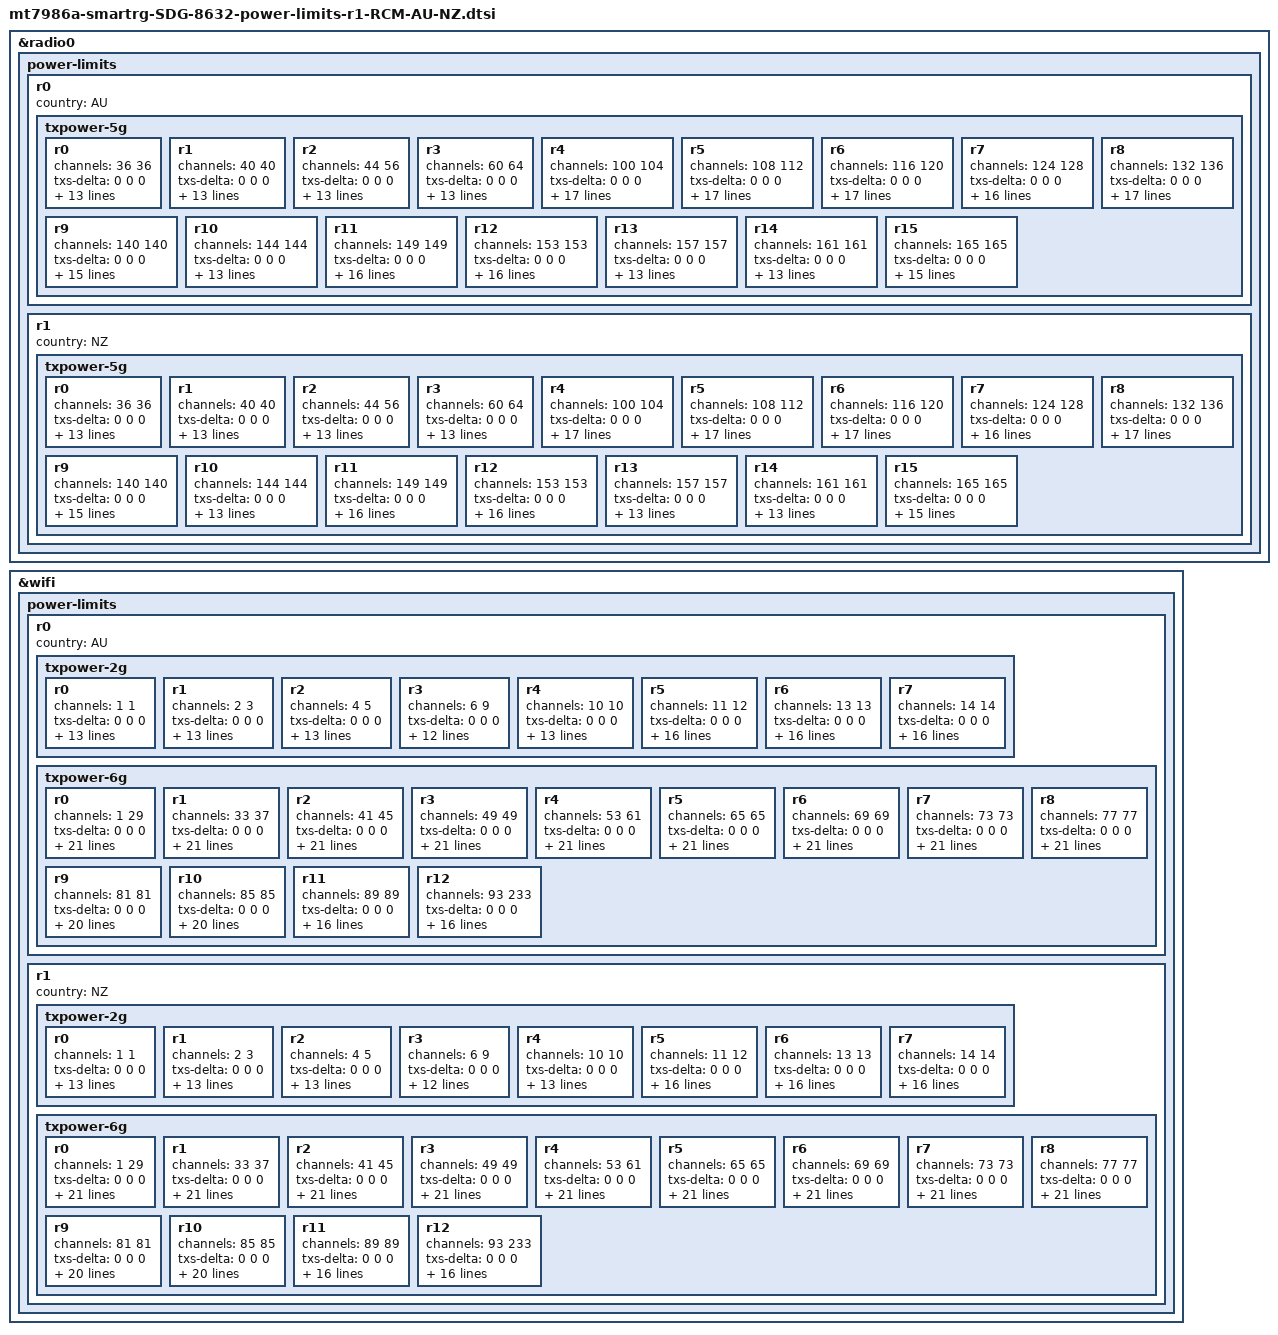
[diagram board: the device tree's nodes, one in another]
// SPDX-License-Identifier: (GPL-2.0 OR MIT)
/*
 * Copyright (C) 2022 SmartRG Inc.
 * Author: Chad Monroe <chad.monroe@smartrg.com>
 */

&radio0 {
	power-limits {
		r0 {
			country = "AU";

			txpower-5g {
				r0 {
					channels = <36 36>;
					txs-delta = <0 0 0>;
					rates-ofdm = <28 28 28 28 28 28 28 28>;
					rates-mcs =
					<2 34 34 34 34 34 34 34 34 34 34>,
					<2 33 33 33 33 33 33 33 33 33 33>;
					rates-ru =
					<5 34 34 34 34 34 34 34 34 34 34 34 34>,
					<2 33 33 33 33 33 33 33 33 33 33 33 33>;
					paths-ofdm = <1 28 28 28 28>;
					paths-ofdm-bf = <1 28 28 28>;
					paths-ru =
					<5 34 34 34 34 34 34 34 34 34 34>,
					<2 33 33 33 33 33 33 33 33 33 33>;
					paths-ru-bf =
					<3 31 31 31 31 31 31 31 31 31 31>,
					<2 0 31 31 31 31 31 31 31 31 31>,
					<2 0 30 30 30 30 30 30 30 30 30>;
				};
				r1 {
					channels = <40 40>;
					txs-delta = <0 0 0>;
					rates-ofdm = <30 30 30 30 30 30 30 30>;
					rates-mcs =
					<2 34 34 34 34 34 34 34 34 34 34>,
					<2 33 33 33 33 33 33 33 33 33 33>;
					rates-ru =
					<5 34 34 34 34 34 34 34 34 34 34 34 34>,
					<2 33 33 33 33 33 33 33 33 33 33 33 33>;
					paths-ofdm = <1 30 30 30 30>;
					paths-ofdm-bf = <1 30 30 30>;
					paths-ru =
					<5 34 34 34 34 34 34 34 34 34 34>,
					<2 33 33 33 33 33 33 33 33 33 33>;
					paths-ru-bf =
					<3 31 31 31 31 31 31 31 31 31 31>,
					<2 0 31 31 31 31 31 31 31 31 31>,
					<2 0 30 30 30 30 30 30 30 30 30>;
				};
				r2 {
					channels = <44 56>;
					txs-delta = <0 0 0>;
					rates-ofdm = <30 30 30 30 30 30 30 30>;
					rates-mcs =
					<2 34 34 34 34 34 34 34 34 34 34>,
					<2 33 33 33 33 33 33 33 33 33 33>;
					rates-ru =
					<5 34 34 34 34 34 34 34 34 34 34 34 34>,
					<2 33 33 33 33 33 33 33 33 33 33 33 33>;
					paths-ofdm = <1 30 30 30 30>;
					paths-ofdm-bf = <1 30 30 30>;
					paths-ru =
					<5 34 34 34 34 34 34 34 34 34 34>,
					<2 33 33 33 33 33 33 33 33 33 33>;
					paths-ru-bf =
					<3 31 31 31 31 31 31 31 31 31 31>,
					<1 0 31 31 31 31 31 31 31 31 31>,
					<3 0 30 30 30 30 30 30 30 30 30>;
				};
				r3 {
					channels = <60 64>;
					txs-delta = <0 0 0>;
					rates-ofdm = <30 30 30 30 30 30 30 30>;
					rates-mcs =
					<1 34 34 34 34 34 34 34 34 34 34>,
					<3 33 33 33 33 33 33 33 33 33 33>;
					rates-ru =
					<4 34 34 34 34 34 34 34 34 34 34 34 34>,
					<3 33 33 33 33 33 33 33 33 33 33 33 33>;
					paths-ofdm = <1 30 30 30 30>;
					paths-ofdm-bf = <1 30 30 30>;
					paths-ru =
					<4 34 34 34 34 34 34 34 34 34 34>,
					<3 33 33 33 33 33 33 33 33 33 33>;
					paths-ru-bf =
					<3 31 31 31 31 31 31 31 31 31 31>,
					<1 0 31 31 31 31 31 31 31 31 31>,
					<3 0 30 30 30 30 30 30 30 30 30>;
				};
				r4 {
					channels = <100 104>;
					txs-delta = <0 0 0>;
					rates-ofdm = <39 39 39 39 39 39 39 39>;
					rates-mcs =
					<1 37 37 37 37 37 37 37 37 37 37>,
					<1 34 34 34 34 34 34 34 34 34 34>,
					<2 32 32 32 32 32 32 32 32 32 32>;
					rates-ru =
					<4 37 37 37 37 37 37 37 37 37 37 37 37>,
					<1 34 34 34 34 34 34 34 34 34 34 34 34>,
					<2 32 32 32 32 32 32 32 32 32 32 32 32>;
					paths-ofdm = <1 39 39 39 39>;
					paths-ofdm-bf = <1 39 39 39>;
					paths-ru =
					<4 37 37 37 37 37 37 37 37 37 37>,
					<1 34 34 34 34 34 34 34 34 34 34>,
					<2 32 32 32 32 32 32 32 32 32 32>;
					paths-ru-bf =
					<3 38 38 38 38 38 38 38 38 38 38>,
					<1 0 38 38 38 38 38 38 38 38 38>,
					<1 0 35 35 35 35 35 35 35 35 35>,
					<2 0 34 34 34 34 34 34 34 34 34>;
				};
				r5 {
					channels = <108 112>;
					txs-delta = <0 0 0>;
					rates-ofdm = <39 39 39 39 39 39 39 39>;
					rates-mcs =
					<1 37 37 37 37 37 37 37 37 37 37>,
					<1 35 35 35 35 35 35 35 35 35 35>,
					<2 32 32 32 32 32 32 32 32 32 32>;
					rates-ru =
					<4 37 37 37 37 37 37 37 37 37 37 37 37>,
					<1 35 35 35 35 35 35 35 35 35 35 35 35>,
					<2 32 32 32 32 32 32 32 32 32 32 32 32>;
					paths-ofdm = <1 39 39 39 39>;
					paths-ofdm-bf = <1 39 39 39>;
					paths-ru =
					<4 37 37 37 37 37 37 37 37 37 37>,
					<1 35 35 35 35 35 35 35 35 35 35>,
					<2 32 32 32 32 32 32 32 32 32 32>;
					paths-ru-bf =
					<3 38 38 38 38 38 38 38 38 38 38>,
					<1 0 38 38 38 38 38 38 38 38 38>,
					<1 0 36 36 36 36 36 36 36 36 36>,
					<2 0 34 34 34 34 34 34 34 34 34>;
				};
				r6 {
					channels = <116 120>;
					txs-delta = <0 0 0>;
					rates-ofdm = <39 39 39 39 39 39 39 39>;
					rates-mcs =
					<1 37 37 37 37 37 37 37 37 37 37>,
					<1 36 36 36 36 36 36 36 36 36 36>,
					<2 39 39 39 39 39 39 39 39 39 39>;
					rates-ru =
					<4 37 37 37 37 37 37 37 37 37 37 37 37>,
					<1 36 36 36 36 36 36 36 36 36 36 36 36>,
					<2 39 39 39 39 39 39 39 39 39 39 39 39>;
					paths-ofdm = <1 39 39 39 39>;
					paths-ofdm-bf = <1 39 39 39>;
					paths-ru =
					<4 37 37 37 37 37 37 37 37 37 37>,
					<1 36 36 36 36 36 36 36 36 36 36>,
					<2 39 39 39 39 39 39 39 39 39 39>;
					paths-ru-bf =
					<3 38 38 38 38 38 38 38 38 38 38>,
					<1 0 38 38 38 38 38 38 38 38 38>,
					<1 0 37 37 37 37 37 37 37 37 37>,
					<2 0 38 38 38 38 38 38 38 38 38>;
				};
				r7 {
					channels = <124 128>;
					txs-delta = <0 0 0>;
					rates-ofdm = <38 38 38 38 38 38 38 38>;
					rates-mcs =
					<1 36 36 36 36 36 36 36 36 36 36>,
					<1 37 37 37 37 37 37 37 37 37 37>,
					<2 39 39 39 39 39 39 39 39 39 39>;
					rates-ru =
					<4 36 36 36 36 36 36 36 36 36 36 36 36>,
					<1 37 37 37 37 37 37 37 37 37 37 37 37>,
					<2 39 39 39 39 39 39 39 39 39 39 39 39>;
					paths-ofdm = <1 38 38 38 38>;
					paths-ofdm-bf = <1 38 38 38>;
					paths-ru =
					<4 36 36 36 36 36 36 36 36 36 36>,
					<1 37 37 37 37 37 37 37 37 37 37>,
					<2 39 39 39 39 39 39 39 39 39 39>;
					paths-ru-bf =
					<3 37 37 37 37 37 37 37 37 37 37>,
					<1 0 37 37 37 37 37 37 37 37 37>,
					<3 0 38 38 38 38 38 38 38 38 38>;
				};
				r8 {
					channels = <132 136>;
					txs-delta = <0 0 0>;
					rates-ofdm = <37 37 37 37 37 37 37 37>;
					rates-mcs =
					<1 35 35 35 35 35 35 35 35 35 35>,
					<1 38 38 38 38 38 38 38 38 38 38>,
					<2 32 32 32 32 32 32 32 32 32 32>;
					rates-ru =
					<4 35 35 35 35 35 35 35 35 35 35 35 35>,
					<1 38 38 38 38 38 38 38 38 38 38 38 38>,
					<2 32 32 32 32 32 32 32 32 32 32 32 32>;
					paths-ofdm = <1 37 37 37 37>;
					paths-ofdm-bf = <1 37 37 37>;
					paths-ru =
					<4 35 35 35 35 35 35 35 35 35 35>,
					<1 38 38 38 38 38 38 38 38 38 38>,
					<2 32 32 32 32 32 32 32 32 32 32>;
					paths-ru-bf =
					<3 36 36 36 36 36 36 36 36 36 36>,
					<1 0 36 36 36 36 36 36 36 36 36>,
					<1 0 39 39 39 39 39 39 39 39 39>,
					<2 0 34 34 34 34 34 34 34 34 34>;
				};
				r9 {
					channels = <140 140>;
					txs-delta = <0 0 0>;
					rates-ofdm = <36 36 36 36 36 36 36 36>;
					rates-mcs =
					<1 34 34 34 34 34 34 34 34 34 34>,
					<1 38 38 38 38 38 38 38 38 38 38>,
					<2 32 32 32 32 32 32 32 32 32 32>;
					rates-ru =
					<4 34 34 34 34 34 34 34 34 34 34 34 34>,
					<1 38 38 38 38 38 38 38 38 38 38 38 38>,
					<2 32 32 32 32 32 32 32 32 32 32 32 32>;
					paths-ofdm = <1 36 36 36 36>;
					paths-ofdm-bf = <1 36 36 36>;
					paths-ru =
					<5 34 34 34 34 34 34 34 34 34 34>,
					<2 32 32 32 32 32 32 32 32 32 32>;
					paths-ru-bf =
					<3 35 35 35 35 35 35 35 35 35 35>,
					<2 0 35 35 35 35 35 35 35 35 35>,
					<2 0 34 34 34 34 34 34 34 34 34>;
				};
				r10 {
					channels = <144 144>;
					txs-delta = <0 0 0>;
					rates-ofdm = <36 36 36 36 36 36 36 36>;
					rates-mcs =
					<2 34 34 34 34 34 34 34 34 34 34>,
					<2 32 32 32 32 32 32 32 32 32 32>;
					rates-ru =
					<5 34 34 34 34 34 34 34 34 34 34 34 34>,
					<2 32 32 32 32 32 32 32 32 32 32 32 32>;
					paths-ofdm = <1 36 36 36 36>;
					paths-ofdm-bf = <1 36 36 36>;
					paths-ru =
					<5 34 34 34 34 34 34 34 34 34 34>,
					<2 32 32 32 32 32 32 32 32 32 32>;
					paths-ru-bf =
					<3 35 35 35 35 35 35 35 35 35 35>,
					<2 0 35 35 35 35 35 35 35 35 35>,
					<2 0 34 34 34 34 34 34 34 34 34>;
				};
				r11 {
					channels = <149 149>;
					txs-delta = <0 0 0>;
					rates-ofdm = <49 49 49 49 49 49 49 49>;
					rates-mcs =
					<1 48 48 48 48 48 48 48 48 48 48>,
					<1 46 46 46 46 46 46 46 46 46 46>,
					<2 45 45 45 45 45 45 45 45 45 45>;
					rates-ru =
					<4 48 48 48 48 48 48 48 48 48 48 48 48>,
					<1 46 46 46 46 46 46 46 46 46 46 46 46>,
					<2 45 45 45 45 45 45 45 45 45 45 45 45>;
					paths-ofdm = <1 49 49 49 49>;
					paths-ofdm-bf = <1 49 49 49>;
					paths-ru =
					<4 48 48 48 48 48 48 48 48 48 48>,
					<1 46 46 46 46 46 46 46 46 46 46>,
					<2 45 45 45 45 45 45 45 45 45 45>;
					paths-ru-bf =
					<3 49 49 49 49 49 49 49 49 49 49>,
					<2 0 49 49 49 49 49 49 49 49 49>,
					<2 0 46 46 46 46 46 46 46 46 46>;
				};
				r12 {
					channels = <153 153>;
					txs-delta = <0 0 0>;
					rates-ofdm = <49 49 49 49 49 49 49 49>;
					rates-mcs =
					<1 48 48 48 48 48 48 48 48 48 48>,
					<1 47 47 47 47 47 47 47 47 47 47>,
					<2 45 45 45 45 45 45 45 45 45 45>;
					rates-ru =
					<4 48 48 48 48 48 48 48 48 48 48 48 48>,
					<1 47 47 47 47 47 47 47 47 47 47 47 47>,
					<2 45 45 45 45 45 45 45 45 45 45 45 45>;
					paths-ofdm = <1 49 49 49 49>;
					paths-ofdm-bf = <1 49 49 49>;
					paths-ru =
					<4 48 48 48 48 48 48 48 48 48 48>,
					<1 46 46 46 46 46 46 46 46 46 46>,
					<2 45 45 45 45 45 45 45 45 45 45>;
					paths-ru-bf =
					<3 49 49 49 49 49 49 49 49 49 49>,
					<2 0 49 49 49 49 49 49 49 49 49>,
					<2 0 46 46 46 46 46 46 46 46 46>;
				};
				r13 {
					channels = <157 157>;
					txs-delta = <0 0 0>;
					rates-ofdm = <48 48 48 48 48 48 48 48>;
					rates-mcs =
					<2 47 47 47 47 47 47 47 47 47 47>,
					<2 45 45 45 45 45 45 45 45 45 45>;
					rates-ru =
					<5 47 47 47 47 47 47 47 47 47 47 47 47>,
					<2 45 45 45 45 45 45 45 45 45 45 45 45>;
					paths-ofdm = <1 48 48 48 48>;
					paths-ofdm-bf = <1 48 48 48>;
					paths-ru =
					<5 47 47 47 47 47 47 47 47 47 47>,
					<2 45 45 45 45 45 45 45 45 45 45>;
					paths-ru-bf =
					<3 48 48 48 48 48 48 48 48 48 48>,
					<2 0 48 48 48 48 48 48 48 48 48>,
					<2 0 46 46 46 46 46 46 46 46 46>;
				};
				r14 {
					channels = <161 161>;
					txs-delta = <0 0 0>;
					rates-ofdm = <47 47 47 47 47 47 47 47>;
					rates-mcs =
					<2 47 47 47 47 47 47 47 47 47 47>,
					<2 45 45 45 45 45 45 45 45 45 45>;
					rates-ru =
					<5 47 47 47 47 47 47 47 47 47 47 47 47>,
					<2 45 45 45 45 45 45 45 45 45 45 45 45>;
					paths-ofdm = <1 47 47 47 47>;
					paths-ofdm-bf = <1 47 47 47>;
					paths-ru =
					<5 47 47 47 47 47 47 47 47 47 47>,
					<2 45 45 45 45 45 45 45 45 45 45>;
					paths-ru-bf =
					<3 48 48 48 48 48 48 48 48 48 48>,
					<2 0 48 48 48 48 48 48 48 48 48>,
					<2 0 46 46 46 46 46 46 46 46 46>;
				};
				r15 {
					channels = <165 165>;
					txs-delta = <0 0 0>;
					rates-ofdm = <46 46 46 46 46 46 46 46>;
					rates-mcs =
					<1 46 46 46 46 46 46 46 46 46 46>,
					<1 47 47 47 47 47 47 47 47 47 47>,
					<2 45 45 45 45 45 45 45 45 45 45>;
					rates-ru =
					<4 46 46 46 46 46 46 46 46 46 46 46 46>,
					<1 47 47 47 47 47 47 47 47 47 47 47 47>,
					<2 45 45 45 45 45 45 45 45 45 45 45 45>;
					paths-ofdm = <1 46 46 46 46>;
					paths-ofdm-bf = <1 46 46 46>;
					paths-ru =
					<4 46 46 46 46 46 46 46 46 46 46>,
					<1 47 47 47 47 47 47 47 47 47 47>,
					<2 45 45 45 45 45 45 45 45 45 45>;
					paths-ru-bf =
					<3 46 46 46 46 46 46 46 46 46 46>,
					<4 0 46 46 46 46 46 46 46 46 46>;
				};
			};
		};

		r1 {
			country = "NZ";

			txpower-5g {
				r0 {
					channels = <36 36>;
					txs-delta = <0 0 0>;
					rates-ofdm = <28 28 28 28 28 28 28 28>;
					rates-mcs =
					<2 34 34 34 34 34 34 34 34 34 34>,
					<2 33 33 33 33 33 33 33 33 33 33>;
					rates-ru =
					<5 34 34 34 34 34 34 34 34 34 34 34 34>,
					<2 33 33 33 33 33 33 33 33 33 33 33 33>;
					paths-ofdm = <1 28 28 28 28>;
					paths-ofdm-bf = <1 28 28 28>;
					paths-ru =
					<5 34 34 34 34 34 34 34 34 34 34>,
					<2 33 33 33 33 33 33 33 33 33 33>;
					paths-ru-bf =
					<3 31 31 31 31 31 31 31 31 31 31>,
					<2 0 31 31 31 31 31 31 31 31 31>,
					<2 0 30 30 30 30 30 30 30 30 30>;
				};
				r1 {
					channels = <40 40>;
					txs-delta = <0 0 0>;
					rates-ofdm = <30 30 30 30 30 30 30 30>;
					rates-mcs =
					<2 34 34 34 34 34 34 34 34 34 34>,
					<2 33 33 33 33 33 33 33 33 33 33>;
					rates-ru =
					<5 34 34 34 34 34 34 34 34 34 34 34 34>,
					<2 33 33 33 33 33 33 33 33 33 33 33 33>;
					paths-ofdm = <1 30 30 30 30>;
					paths-ofdm-bf = <1 30 30 30>;
					paths-ru =
					<5 34 34 34 34 34 34 34 34 34 34>,
					<2 33 33 33 33 33 33 33 33 33 33>;
					paths-ru-bf =
					<3 31 31 31 31 31 31 31 31 31 31>,
					<2 0 31 31 31 31 31 31 31 31 31>,
					<2 0 30 30 30 30 30 30 30 30 30>;
				};
				r2 {
					channels = <44 56>;
					txs-delta = <0 0 0>;
					rates-ofdm = <30 30 30 30 30 30 30 30>;
					rates-mcs =
					<2 34 34 34 34 34 34 34 34 34 34>,
					<2 33 33 33 33 33 33 33 33 33 33>;
					rates-ru =
					<5 34 34 34 34 34 34 34 34 34 34 34 34>,
					<2 33 33 33 33 33 33 33 33 33 33 33 33>;
					paths-ofdm = <1 30 30 30 30>;
					paths-ofdm-bf = <1 30 30 30>;
					paths-ru =
					<5 34 34 34 34 34 34 34 34 34 34>,
					<2 33 33 33 33 33 33 33 33 33 33>;
					paths-ru-bf =
					<3 31 31 31 31 31 31 31 31 31 31>,
					<1 0 31 31 31 31 31 31 31 31 31>,
					<3 0 30 30 30 30 30 30 30 30 30>;
				};
				r3 {
					channels = <60 64>;
					txs-delta = <0 0 0>;
					rates-ofdm = <30 30 30 30 30 30 30 30>;
					rates-mcs =
					<1 34 34 34 34 34 34 34 34 34 34>,
					<3 33 33 33 33 33 33 33 33 33 33>;
					rates-ru =
					<4 34 34 34 34 34 34 34 34 34 34 34 34>,
					<3 33 33 33 33 33 33 33 33 33 33 33 33>;
					paths-ofdm = <1 30 30 30 30>;
					paths-ofdm-bf = <1 30 30 30>;
					paths-ru =
					<4 34 34 34 34 34 34 34 34 34 34>,
					<3 33 33 33 33 33 33 33 33 33 33>;
					paths-ru-bf =
					<3 31 31 31 31 31 31 31 31 31 31>,
					<1 0 31 31 31 31 31 31 31 31 31>,
					<3 0 30 30 30 30 30 30 30 30 30>;
				};
				r4 {
					channels = <100 104>;
					txs-delta = <0 0 0>;
					rates-ofdm = <39 39 39 39 39 39 39 39>;
					rates-mcs =
					<1 37 37 37 37 37 37 37 37 37 37>,
					<1 34 34 34 34 34 34 34 34 34 34>,
					<2 32 32 32 32 32 32 32 32 32 32>;
					rates-ru =
					<4 37 37 37 37 37 37 37 37 37 37 37 37>,
					<1 34 34 34 34 34 34 34 34 34 34 34 34>,
					<2 32 32 32 32 32 32 32 32 32 32 32 32>;
					paths-ofdm = <1 39 39 39 39>;
					paths-ofdm-bf = <1 39 39 39>;
					paths-ru =
					<4 37 37 37 37 37 37 37 37 37 37>,
					<1 34 34 34 34 34 34 34 34 34 34>,
					<2 32 32 32 32 32 32 32 32 32 32>;
					paths-ru-bf =
					<3 38 38 38 38 38 38 38 38 38 38>,
					<1 0 38 38 38 38 38 38 38 38 38>,
					<1 0 35 35 35 35 35 35 35 35 35>,
					<2 0 34 34 34 34 34 34 34 34 34>;
				};
				r5 {
					channels = <108 112>;
					txs-delta = <0 0 0>;
					rates-ofdm = <39 39 39 39 39 39 39 39>;
					rates-mcs =
					<1 37 37 37 37 37 37 37 37 37 37>,
					<1 35 35 35 35 35 35 35 35 35 35>,
					<2 32 32 32 32 32 32 32 32 32 32>;
					rates-ru =
					<4 37 37 37 37 37 37 37 37 37 37 37 37>,
					<1 35 35 35 35 35 35 35 35 35 35 35 35>,
					<2 32 32 32 32 32 32 32 32 32 32 32 32>;
					paths-ofdm = <1 39 39 39 39>;
					paths-ofdm-bf = <1 39 39 39>;
					paths-ru =
					<4 37 37 37 37 37 37 37 37 37 37>,
					<1 35 35 35 35 35 35 35 35 35 35>,
					<2 32 32 32 32 32 32 32 32 32 32>;
					paths-ru-bf =
					<3 38 38 38 38 38 38 38 38 38 38>,
					<1 0 38 38 38 38 38 38 38 38 38>,
					<1 0 36 36 36 36 36 36 36 36 36>,
					<2 0 34 34 34 34 34 34 34 34 34>;
				};
				r6 {
					channels = <116 120>;
					txs-delta = <0 0 0>;
					rates-ofdm = <39 39 39 39 39 39 39 39>;
					rates-mcs =
					<1 37 37 37 37 37 37 37 37 37 37>,
					<1 36 36 36 36 36 36 36 36 36 36>,
					<2 39 39 39 39 39 39 39 39 39 39>;
					rates-ru =
					<4 37 37 37 37 37 37 37 37 37 37 37 37>,
					<1 36 36 36 36 36 36 36 36 36 36 36 36>,
					<2 39 39 39 39 39 39 39 39 39 39 39 39>;
					paths-ofdm = <1 39 39 39 39>;
					paths-ofdm-bf = <1 39 39 39>;
					paths-ru =
					<4 37 37 37 37 37 37 37 37 37 37>,
					<1 36 36 36 36 36 36 36 36 36 36>,
					<2 39 39 39 39 39 39 39 39 39 39>;
					paths-ru-bf =
					<3 38 38 38 38 38 38 38 38 38 38>,
					<1 0 38 38 38 38 38 38 38 38 38>,
					<1 0 37 37 37 37 37 37 37 37 37>,
					<2 0 38 38 38 38 38 38 38 38 38>;
				};
				r7 {
					channels = <124 128>;
					txs-delta = <0 0 0>;
					rates-ofdm = <38 38 38 38 38 38 38 38>;
					rates-mcs =
					<1 36 36 36 36 36 36 36 36 36 36>,
					<1 37 37 37 37 37 37 37 37 37 37>,
					<2 39 39 39 39 39 39 39 39 39 39>;
					rates-ru =
					<4 36 36 36 36 36 36 36 36 36 36 36 36>,
					<1 37 37 37 37 37 37 37 37 37 37 37 37>,
					<2 39 39 39 39 39 39 39 39 39 39 39 39>;
					paths-ofdm = <1 38 38 38 38>;
					paths-ofdm-bf = <1 38 38 38>;
					paths-ru =
					<4 36 36 36 36 36 36 36 36 36 36>,
					<1 37 37 37 37 37 37 37 37 37 37>,
					<2 39 39 39 39 39 39 39 39 39 39>;
					paths-ru-bf =
					<3 37 37 37 37 37 37 37 37 37 37>,
					<1 0 37 37 37 37 37 37 37 37 37>,
					<3 0 38 38 38 38 38 38 38 38 38>;
				};
				r8 {
					channels = <132 136>;
					txs-delta = <0 0 0>;
					rates-ofdm = <37 37 37 37 37 37 37 37>;
					rates-mcs =
					<1 35 35 35 35 35 35 35 35 35 35>,
					<1 38 38 38 38 38 38 38 38 38 38>,
					<2 32 32 32 32 32 32 32 32 32 32>;
					rates-ru =
					<4 35 35 35 35 35 35 35 35 35 35 35 35>,
					<1 38 38 38 38 38 38 38 38 38 38 38 38>,
					<2 32 32 32 32 32 32 32 32 32 32 32 32>;
					paths-ofdm = <1 37 37 37 37>;
					paths-ofdm-bf = <1 37 37 37>;
					paths-ru =
					<4 35 35 35 35 35 35 35 35 35 35>,
					<1 38 38 38 38 38 38 38 38 38 38>,
					<2 32 32 32 32 32 32 32 32 32 32>;
					paths-ru-bf =
					<3 36 36 36 36 36 36 36 36 36 36>,
					<1 0 36 36 36 36 36 36 36 36 36>,
					<1 0 39 39 39 39 39 39 39 39 39>,
					<2 0 34 34 34 34 34 34 34 34 34>;
				};
				r9 {
					channels = <140 140>;
					txs-delta = <0 0 0>;
					rates-ofdm = <36 36 36 36 36 36 36 36>;
					rates-mcs =
					<1 34 34 34 34 34 34 34 34 34 34>,
					<1 38 38 38 38 38 38 38 38 38 38>,
					<2 32 32 32 32 32 32 32 32 32 32>;
					rates-ru =
					<4 34 34 34 34 34 34 34 34 34 34 34 34>,
					<1 38 38 38 38 38 38 38 38 38 38 38 38>,
					<2 32 32 32 32 32 32 32 32 32 32 32 32>;
					paths-ofdm = <1 36 36 36 36>;
					paths-ofdm-bf = <1 36 36 36>;
					paths-ru =
					<5 34 34 34 34 34 34 34 34 34 34>,
					<2 32 32 32 32 32 32 32 32 32 32>;
					paths-ru-bf =
					<3 35 35 35 35 35 35 35 35 35 35>,
					<2 0 35 35 35 35 35 35 35 35 35>,
					<2 0 34 34 34 34 34 34 34 34 34>;
				};
				r10 {
					channels = <144 144>;
					txs-delta = <0 0 0>;
					rates-ofdm = <36 36 36 36 36 36 36 36>;
					rates-mcs =
					<2 34 34 34 34 34 34 34 34 34 34>,
					<2 32 32 32 32 32 32 32 32 32 32>;
					rates-ru =
					<5 34 34 34 34 34 34 34 34 34 34 34 34>,
					<2 32 32 32 32 32 32 32 32 32 32 32 32>;
					paths-ofdm = <1 36 36 36 36>;
					paths-ofdm-bf = <1 36 36 36>;
					paths-ru =
					<5 34 34 34 34 34 34 34 34 34 34>,
					<2 32 32 32 32 32 32 32 32 32 32>;
					paths-ru-bf =
					<3 35 35 35 35 35 35 35 35 35 35>,
					<2 0 35 35 35 35 35 35 35 35 35>,
					<2 0 34 34 34 34 34 34 34 34 34>;
				};
				r11 {
					channels = <149 149>;
					txs-delta = <0 0 0>;
					rates-ofdm = <49 49 49 49 49 49 49 49>;
					rates-mcs =
					<1 48 48 48 48 48 48 48 48 48 48>,
					<1 46 46 46 46 46 46 46 46 46 46>,
					<2 45 45 45 45 45 45 45 45 45 45>;
					rates-ru =
					<4 48 48 48 48 48 48 48 48 48 48 48 48>,
					<1 46 46 46 46 46 46 46 46 46 46 46 46>,
					<2 45 45 45 45 45 45 45 45 45 45 45 45>;
					paths-ofdm = <1 49 49 49 49>;
					paths-ofdm-bf = <1 49 49 49>;
					paths-ru =
					<4 48 48 48 48 48 48 48 48 48 48>,
					<1 46 46 46 46 46 46 46 46 46 46>,
					<2 45 45 45 45 45 45 45 45 45 45>;
					paths-ru-bf =
					<3 49 49 49 49 49 49 49 49 49 49>,
					<2 0 49 49 49 49 49 49 49 49 49>,
					<2 0 46 46 46 46 46 46 46 46 46>;
				};
				r12 {
					channels = <153 153>;
					txs-delta = <0 0 0>;
					rates-ofdm = <49 49 49 49 49 49 49 49>;
					rates-mcs =
					<1 48 48 48 48 48 48 48 48 48 48>,
					<1 47 47 47 47 47 47 47 47 47 47>,
					<2 45 45 45 45 45 45 45 45 45 45>;
					rates-ru =
					<4 48 48 48 48 48 48 48 48 48 48 48 48>,
					<1 47 47 47 47 47 47 47 47 47 47 47 47>,
					<2 45 45 45 45 45 45 45 45 45 45 45 45>;
					paths-ofdm = <1 49 49 49 49>;
					paths-ofdm-bf = <1 49 49 49>;
					paths-ru =
					<4 48 48 48 48 48 48 48 48 48 48>,
					<1 46 46 46 46 46 46 46 46 46 46>,
					<2 45 45 45 45 45 45 45 45 45 45>;
					paths-ru-bf =
					<3 49 49 49 49 49 49 49 49 49 49>,
					<2 0 49 49 49 49 49 49 49 49 49>,
					<2 0 46 46 46 46 46 46 46 46 46>;
				};
				r13 {
					channels = <157 157>;
					txs-delta = <0 0 0>;
					rates-ofdm = <48 48 48 48 48 48 48 48>;
					rates-mcs =
					<2 47 47 47 47 47 47 47 47 47 47>,
					<2 45 45 45 45 45 45 45 45 45 45>;
					rates-ru =
					<5 47 47 47 47 47 47 47 47 47 47 47 47>,
					<2 45 45 45 45 45 45 45 45 45 45 45 45>;
					paths-ofdm = <1 48 48 48 48>;
					paths-ofdm-bf = <1 48 48 48>;
					paths-ru =
					<5 47 47 47 47 47 47 47 47 47 47>,
					<2 45 45 45 45 45 45 45 45 45 45>;
					paths-ru-bf =
					<3 48 48 48 48 48 48 48 48 48 48>,
					<2 0 48 48 48 48 48 48 48 48 48>,
					<2 0 46 46 46 46 46 46 46 46 46>;
				};
				r14 {
					channels = <161 161>;
					txs-delta = <0 0 0>;
					rates-ofdm = <47 47 47 47 47 47 47 47>;
					rates-mcs =
					<2 47 47 47 47 47 47 47 47 47 47>,
					<2 45 45 45 45 45 45 45 45 45 45>;
					rates-ru =
					<5 47 47 47 47 47 47 47 47 47 47 47 47>,
					<2 45 45 45 45 45 45 45 45 45 45 45 45>;
					paths-ofdm = <1 47 47 47 47>;
					paths-ofdm-bf = <1 47 47 47>;
					paths-ru =
					<5 47 47 47 47 47 47 47 47 47 47>,
					<2 45 45 45 45 45 45 45 45 45 45>;
					paths-ru-bf =
					<3 48 48 48 48 48 48 48 48 48 48>,
					<2 0 48 48 48 48 48 48 48 48 48>,
					<2 0 46 46 46 46 46 46 46 46 46>;
				};
				r15 {
					channels = <165 165>;
					txs-delta = <0 0 0>;
					rates-ofdm = <46 46 46 46 46 46 46 46>;
					rates-mcs =
					<1 46 46 46 46 46 46 46 46 46 46>,
					<1 47 47 47 47 47 47 47 47 47 47>,
					<2 45 45 45 45 45 45 45 45 45 45>;
					rates-ru =
					<4 46 46 46 46 46 46 46 46 46 46 46 46>,
					<1 47 47 47 47 47 47 47 47 47 47 47 47>,
					<2 45 45 45 45 45 45 45 45 45 45 45 45>;
					paths-ofdm = <1 46 46 46 46>;
					paths-ofdm-bf = <1 46 46 46>;
					paths-ru =
					<4 46 46 46 46 46 46 46 46 46 46>,
					<1 47 47 47 47 47 47 47 47 47 47>,
					<2 45 45 45 45 45 45 45 45 45 45>;
					paths-ru-bf =
					<3 46 46 46 46 46 46 46 46 46 46>,
					<4 0 46 46 46 46 46 46 46 46 46>;
				};
			};
		};
	};
};

&wifi {
	power-limits {
		r0 {
			country = "AU";

			txpower-2g {
				r0 {
					channels = <1 1>;
					txs-delta = <0 0 0>;
					rates-cck = <50 50 50 50>;
					rates-ofdm = <56 56 56 56 56 56 56 56>;
					rates-mcs =
					<4 56 56 56 56 56 56 56 56 56 56>;
					rates-ru =
					<7 56 56 56 56 56 56 56 56 56 56 56 56>;
					paths-cck = <50 50 50 50>;
					paths-ofdm = <1 56 56 56 56>;
					paths-ofdm-bf = <1 50 50 50>;
					paths-ru =
					<5 56 56 56 56 56 56 56 56 56 56>,
					<2 27 27 27 27 27 27 27 27 27 27>;
					paths-ru-bf =
					<3 26 26 26 26 26 26 26 26 26 26>,
					<1 0 26 26 26 26 26 26 26 26 26>,
					<3 0 27 27 27 27 27 27 27 27 27>;
				};
				r1 {
					channels = <2 3>;
					txs-delta = <0 0 0>;
					rates-cck = <51 51 51 51>;
					rates-ofdm = <57 57 57 57 57 57 57 57>;
					rates-mcs =
					<4 56 56 56 56 56 56 56 56 56 56>;
					rates-ru =
					<7 56 56 56 56 56 56 56 56 56 56 56 56>;
					paths-cck = <51 51 51 51>;
					paths-ofdm = <1 57 57 57 57>;
					paths-ofdm-bf = <1 51 51 51>;
					paths-ru =
					<5 56 56 56 56 56 56 56 56 56 56>,
					<2 27 27 27 27 27 27 27 27 27 27>;
					paths-ru-bf =
					<3 26 26 26 26 26 26 26 26 26 26>,
					<1 0 26 26 26 26 26 26 26 26 26>,
					<3 0 27 27 27 27 27 27 27 27 27>;
				};
				r2 {
					channels = <4 5>;
					txs-delta = <0 0 0>;
					rates-cck = <51 51 51 51>;
					rates-ofdm = <57 57 57 57 57 57 57 57>;
					rates-mcs =
					<4 56 56 56 56 56 56 56 56 56 56>;
					rates-ru =
					<7 56 56 56 56 56 56 56 56 56 56 56 56>;
					paths-cck = <51 51 51 51>;
					paths-ofdm = <1 57 57 57 57>;
					paths-ofdm-bf = <1 51 51 51>;
					paths-ru =
					<5 56 56 56 56 56 56 56 56 56 56>,
					<2 26 26 26 26 26 26 26 26 26 26>;
					paths-ru-bf =
					<3 25 25 25 25 25 25 25 25 25 25>,
					<1 0 25 25 25 25 25 25 25 25 25>,
					<3 0 26 26 26 26 26 26 26 26 26>;
				};
				r3 {
					channels = <6 9>;
					txs-delta = <0 0 0>;
					rates-cck = <51 51 51 51>;
					rates-ofdm = <57 57 57 57 57 57 57 57>;
					rates-mcs =
					<4 56 56 56 56 56 56 56 56 56 56>;
					rates-ru =
					<7 56 56 56 56 56 56 56 56 56 56 56 56>;
					paths-cck = <51 51 51 51>;
					paths-ofdm = <1 57 57 57 57>;
					paths-ofdm-bf = <1 51 51 51>;
					paths-ru =
					<5 56 56 56 56 56 56 56 56 56 56>,
					<2 25 25 25 25 25 25 25 25 25 25>;
					paths-ru-bf =
					<3 25 25 25 25 25 25 25 25 25 25>,
					<4 0 25 25 25 25 25 25 25 25 25>;
				};
				r4 {
					channels = <10 10>;
					txs-delta = <0 0 0>;
					rates-cck = <51 51 51 51>;
					rates-ofdm = <57 57 57 57 57 57 57 57>;
					rates-mcs =
					<4 56 56 56 56 56 56 56 56 56 56>;
					rates-ru =
					<7 56 56 56 56 56 56 56 56 56 56 56 56>;
					paths-cck = <51 51 51 51>;
					paths-ofdm = <1 57 57 57 57>;
					paths-ofdm-bf = <1 51 51 51>;
					paths-ru =
					<5 56 56 56 56 56 56 56 56 56 56>,
					<2 26 26 26 26 26 26 26 26 26 26>;
					paths-ru-bf =
					<3 25 25 25 25 25 25 25 25 25 25>,
					<1 0 25 25 25 25 25 25 25 25 25>,
					<3 0 26 26 26 26 26 26 26 26 26>;
				};
				r5 {
					channels = <11 12>;
					txs-delta = <0 0 0>;
					rates-cck = <51 51 51 51>;
					rates-ofdm = <57 57 57 57 57 57 57 57>;
					rates-mcs =
					<1 56 56 56 56 56 56 56 56 56 56>,
					<3 55 55 55 55 55 55 55 55 55 55>;
					rates-ru =
					<4 56 56 56 56 56 56 56 56 56 56 56 56>,
					<3 55 55 55 55 55 55 55 55 55 55 55 55>;
					paths-cck = <51 51 51 51>;
					paths-ofdm = <1 57 57 57 57>;
					paths-ofdm-bf = <1 51 51 51>;
					paths-ru =
					<4 56 56 56 56 56 56 56 56 56 56>,
					<1 55 55 55 55 55 55 55 55 55 55>,
					<2 26 26 26 26 26 26 26 26 26 26>;
					paths-ru-bf =
					<3 25 25 25 25 25 25 25 25 25 25>,
					<1 0 25 25 25 25 25 25 25 25 25>,
					<3 0 26 26 26 26 26 26 26 26 26>;
				};
				r6 {
					channels = <13 13>;
					txs-delta = <0 0 0>;
					rates-cck = <51 51 51 51>;
					rates-ofdm = <56 56 56 56 56 56 56 56>;
					rates-mcs =
					<1 56 56 56 56 56 56 56 56 56 56>,
					<3 55 55 55 55 55 55 55 55 55 55>;
					rates-ru =
					<4 56 56 56 56 56 56 56 56 56 56 56 56>,
					<3 55 55 55 55 55 55 55 55 55 55 55 55>;
					paths-cck = <51 51 51 51>;
					paths-ofdm = <1 56 56 56 56>;
					paths-ofdm-bf = <1 51 51 51>;
					paths-ru =
					<4 56 56 56 56 56 56 56 56 56 56>,
					<1 55 55 55 55 55 55 55 55 55 55>,
					<2 26 26 26 26 26 26 26 26 26 26>;
					paths-ru-bf =
					<3 25 25 25 25 25 25 25 25 25 25>,
					<1 0 25 25 25 25 25 25 25 25 25>,
					<3 0 26 26 26 26 26 26 26 26 26>;
				};
				r7 {
					channels = <14 14>;
					txs-delta = <0 0 0>;
					rates-cck = <50 50 50 50>;
					rates-ofdm = <56 56 56 56 56 56 56 56>;
					rates-mcs =
					<1 56 56 56 56 56 56 56 56 56 56>,
					<1 55 55 55 55 55 55 55 55 55 55>,
					<2 37 37 37 37 37 37 37 37 37 37>;
					rates-ru =
					<4 56 56 56 56 56 56 56 56 56 56 56 56>,
					<3 55 55 55 55 55 55 55 55 55 55 55 55>;
					paths-cck = <50 50 50 50>;
					paths-ofdm = <1 56 56 56 56>;
					paths-ofdm-bf = <1 50 50 50>;
					paths-ru =
					<4 56 56 56 56 56 56 56 56 56 56>,
					<1 55 55 55 55 55 55 55 55 55 55>,
					<2 25 25 25 25 25 25 25 25 25 25>;
					paths-ru-bf =
					<3 25 25 25 25 25 25 25 25 25 25>,
					<4 0 25 25 25 25 25 25 25 25 25>;
				};
			};

			txpower-6g {
				r0 {
					channels = <1 29>;
					txs-delta = <0 0 0>;
					rates-ofdm = <26 26 26 26 26 26 26 26>;
					rates-mcs =
					<1 29 29 29 29 29 29 29 29 29 29>,
					<1 31 31 31 31 31 31 31 31 31 31>,
					<1 29 29 29 29 29 29 29 29 29 29>,
					<1 31 31 31 31 31 31 31 31 31 31>;
					rates-ru =
					<4 29 29 29 29 29 29 29 29 29 29 29 29>,
					<1 31 31 31 31 31 31 31 31 31 31 31 31>,
					<1 29 29 29 29 29 29 29 29 29 29 29 29>,
					<1 31 31 31 31 31 31 31 31 31 31 31 31>;
					paths-ofdm = <1 26 26 26 26>;
					paths-ofdm-bf = <1 26 26 26>;
					paths-ru =
					<4 29 29 29 29 29 29 29 29 29 29>,
					<1 31 31 31 31 31 31 31 31 31 31>,
					<1 29 29 29 29 29 29 29 29 29 29>,
					<1 31 31 31 31 31 31 31 31 31 31>;
					paths-ru-bf =
					<3 20 20 20 20 20 20 20 20 20 20>,
					<1 0 20 20 20 20 20 20 20 20 20>,
					<1 0 21 21 21 21 21 21 21 21 21>,
					<1 0 20 20 20 20 20 20 20 20 20>,
					<1 0 22 22 22 22 22 22 22 22 22>;
				};
				r1 {
					channels = <33 37>;
					txs-delta = <0 0 0>;
					rates-ofdm = <26 26 26 26 26 26 26 26>;
					rates-mcs =
					<1 29 29 29 29 29 29 29 29 29 29>,
					<1 31 31 31 31 31 31 31 31 31 31>,
					<1 29 29 29 29 29 29 29 29 29 29>,
					<1 31 31 31 31 31 31 31 31 31 31>;
					rates-ru =
					<4 29 29 29 29 29 29 29 29 29 29 29 29>,
					<1 31 31 31 31 31 31 31 31 31 31 31 31>,
					<1 29 29 29 29 29 29 29 29 29 29 29 29>,
					<1 31 31 31 31 31 31 31 31 31 31 31 31>;
					paths-ofdm = <1 26 26 26 26>;
					paths-ofdm-bf = <1 26 26 26>;
					paths-ru =
					<4 29 29 29 29 29 29 29 29 29 29>,
					<1 31 31 31 31 31 31 31 31 31 31>,
					<1 29 29 29 29 29 29 29 29 29 29>,
					<1 31 31 31 31 31 31 31 31 31 31>;
					paths-ru-bf =
					<3 20 20 20 20 20 20 20 20 20 20>,
					<1 0 20 20 20 20 20 20 20 20 20>,
					<1 0 21 21 21 21 21 21 21 21 21>,
					<1 0 20 20 20 20 20 20 20 20 20>,
					<1 0 21 21 21 21 21 21 21 21 21>;
				};
				r2 {
					channels = <41 45>;
					txs-delta = <0 0 0>;
					rates-ofdm = <26 26 26 26 26 26 26 26>;
					rates-mcs =
					<1 29 29 29 29 29 29 29 29 29 29>,
					<1 30 30 30 30 30 30 30 30 30 30>,
					<1 29 29 29 29 29 29 29 29 29 29>,
					<1 31 31 31 31 31 31 31 31 31 31>;
					rates-ru =
					<4 29 29 29 29 29 29 29 29 29 29 29 29>,
					<1 30 30 30 30 30 30 30 30 30 30 30 30>,
					<1 29 29 29 29 29 29 29 29 29 29 29 29>,
					<1 31 31 31 31 31 31 31 31 31 31 31 31>;
					paths-ofdm = <1 26 26 26 26>;
					paths-ofdm-bf = <1 26 26 26>;
					paths-ru =
					<4 29 29 29 29 29 29 29 29 29 29>,
					<1 30 30 30 30 30 30 30 30 30 30>,
					<1 29 29 29 29 29 29 29 29 29 29>,
					<1 31 31 31 31 31 31 31 31 31 31>;
					paths-ru-bf =
					<3 20 20 20 20 20 20 20 20 20 20>,
					<1 0 20 20 20 20 20 20 20 20 20>,
					<1 0 21 21 21 21 21 21 21 21 21>,
					<1 0 20 20 20 20 20 20 20 20 20>,
					<1 0 21 21 21 21 21 21 21 21 21>;
				};
				r3 {
					channels = <49 49>;
					txs-delta = <0 0 0>;
					rates-ofdm = <26 26 26 26 26 26 26 26>;
					rates-mcs =
					<1 29 29 29 29 29 29 29 29 29 29>,
					<1 30 30 30 30 30 30 30 30 30 30>,
					<1 29 29 29 29 29 29 29 29 29 29>,
					<1 31 31 31 31 31 31 31 31 31 31>;
					rates-ru =
					<4 29 29 29 29 29 29 29 29 29 29 29 29>,
					<1 30 30 30 30 30 30 30 30 30 30 30 30>,
					<1 29 29 29 29 29 29 29 29 29 29 29 29>,
					<1 31 31 31 31 31 31 31 31 31 31 31 31>;
					paths-ofdm = <1 26 26 26 26>;
					paths-ofdm-bf = <1 26 26 26>;
					paths-ru =
					<4 29 29 29 29 29 29 29 29 29 29>,
					<1 30 30 30 30 30 30 30 30 30 30>,
					<1 29 29 29 29 29 29 29 29 29 29>,
					<1 31 31 31 31 31 31 31 31 31 31>;
					paths-ru-bf =
					<3 20 20 20 20 20 20 20 20 20 20>,
					<1 0 20 20 20 20 20 20 20 20 20>,
					<1 0 21 21 21 21 21 21 21 21 21>,
					<1 0 19 19 19 19 19 19 19 19 19>,
					<1 0 21 21 21 21 21 21 21 21 21>;
				};
				r4 {
					channels = <53 61>;
					txs-delta = <0 0 0>;
					rates-ofdm = <26 26 26 26 26 26 26 26>;
					rates-mcs =
					<1 29 29 29 29 29 29 29 29 29 29>,
					<1 30 30 30 30 30 30 30 30 30 30>,
					<1 28 28 28 28 28 28 28 28 28 28>,
					<1 31 31 31 31 31 31 31 31 31 31>;
					rates-ru =
					<4 29 29 29 29 29 29 29 29 29 29 29 29>,
					<1 30 30 30 30 30 30 30 30 30 30 30 30>,
					<1 28 28 28 28 28 28 28 28 28 28 28 28>,
					<1 31 31 31 31 31 31 31 31 31 31 31 31>;
					paths-ofdm = <1 26 26 26 26>;
					paths-ofdm-bf = <1 26 26 26>;
					paths-ru =
					<4 29 29 29 29 29 29 29 29 29 29>,
					<1 30 30 30 30 30 30 30 30 30 30>,
					<1 28 28 28 28 28 28 28 28 28 28>,
					<1 31 31 31 31 31 31 31 31 31 31>;
					paths-ru-bf =
					<3 20 20 20 20 20 20 20 20 20 20>,
					<1 0 20 20 20 20 20 20 20 20 20>,
					<1 0 21 21 21 21 21 21 21 21 21>,
					<1 0 19 19 19 19 19 19 19 19 19>,
					<1 0 21 21 21 21 21 21 21 21 21>;
				};
				r5 {
					channels = <65 65>;
					txs-delta = <0 0 0>;
					rates-ofdm = <26 26 26 26 26 26 26 26>;
					rates-mcs =
					<1 28 28 28 28 28 28 28 28 28 28>,
					<1 30 30 30 30 30 30 30 30 30 30>,
					<1 28 28 28 28 28 28 28 28 28 28>,
					<1 31 31 31 31 31 31 31 31 31 31>;
					rates-ru =
					<4 28 28 28 28 28 28 28 28 28 28 28 28>,
					<1 30 30 30 30 30 30 30 30 30 30 30 30>,
					<1 28 28 28 28 28 28 28 28 28 28 28 28>,
					<1 31 31 31 31 31 31 31 31 31 31 31 31>;
					paths-ofdm = <1 26 26 26 26>;
					paths-ofdm-bf = <1 26 26 26>;
					paths-ru =
					<4 28 28 28 28 28 28 28 28 28 28>,
					<1 30 30 30 30 30 30 30 30 30 30>,
					<1 28 28 28 28 28 28 28 28 28 28>,
					<1 31 31 31 31 31 31 31 31 31 31>;
					paths-ru-bf =
					<3 20 20 20 20 20 20 20 20 20 20>,
					<1 0 20 20 20 20 20 20 20 20 20>,
					<1 0 21 21 21 21 21 21 21 21 21>,
					<1 0 18 18 18 18 18 18 18 18 18>,
					<1 0 20 20 20 20 20 20 20 20 20>;
				};
				r6 {
					channels = <69 69>;
					txs-delta = <0 0 0>;
					rates-ofdm = <26 26 26 26 26 26 26 26>;
					rates-mcs =
					<1 28 28 28 28 28 28 28 28 28 28>,
					<1 29 29 29 29 29 29 29 29 29 29>,
					<1 28 28 28 28 28 28 28 28 28 28>,
					<1 31 31 31 31 31 31 31 31 31 31>;
					rates-ru =
					<4 28 28 28 28 28 28 28 28 28 28 28 28>,
					<1 29 29 29 29 29 29 29 29 29 29 29 29>,
					<1 28 28 28 28 28 28 28 28 28 28 28 28>,
					<1 31 31 31 31 31 31 31 31 31 31 31 31>;
					paths-ofdm = <1 26 26 26 26>;
					paths-ofdm-bf = <1 26 26 26>;
					paths-ru =
					<4 28 28 28 28 28 28 28 28 28 28>,
					<1 29 29 29 29 29 29 29 29 29 29>,
					<1 28 28 28 28 28 28 28 28 28 28>,
					<1 31 31 31 31 31 31 31 31 31 31>;
					paths-ru-bf =
					<3 20 20 20 20 20 20 20 20 20 20>,
					<1 0 20 20 20 20 20 20 20 20 20>,
					<1 0 21 21 21 21 21 21 21 21 21>,
					<1 0 18 18 18 18 18 18 18 18 18>,
					<1 0 20 20 20 20 20 20 20 20 20>;
				};
				r7 {
					channels = <73 73>;
					txs-delta = <0 0 0>;
					rates-ofdm = <26 26 26 26 26 26 26 26>;
					rates-mcs =
					<1 28 28 28 28 28 28 28 28 28 28>,
					<1 29 29 29 29 29 29 29 29 29 29>,
					<1 28 28 28 28 28 28 28 28 28 28>,
					<1 31 31 31 31 31 31 31 31 31 31>;
					rates-ru =
					<4 28 28 28 28 28 28 28 28 28 28 28 28>,
					<1 29 29 29 29 29 29 29 29 29 29 29 29>,
					<1 28 28 28 28 28 28 28 28 28 28 28 28>,
					<1 31 31 31 31 31 31 31 31 31 31 31 31>;
					paths-ofdm = <1 26 26 26 26>;
					paths-ofdm-bf = <1 26 26 26>;
					paths-ru =
					<4 28 28 28 28 28 28 28 28 28 28>,
					<1 29 29 29 29 29 29 29 29 29 29>,
					<1 28 28 28 28 28 28 28 28 28 28>,
					<1 31 31 31 31 31 31 31 31 31 31>;
					paths-ru-bf =
					<3 19 19 19 19 19 19 19 19 19 19>,
					<1 0 19 19 19 19 19 19 19 19 19>,
					<1 0 20 20 20 20 20 20 20 20 20>,
					<1 0 18 18 18 18 18 18 18 18 18>,
					<1 0 20 20 20 20 20 20 20 20 20>;
				};
				r8 {
					channels = <77 77>;
					txs-delta = <0 0 0>;
					rates-ofdm = <26 26 26 26 26 26 26 26>;
					rates-mcs =
					<1 27 27 27 27 27 27 27 27 27 27>,
					<1 29 29 29 29 29 29 29 29 29 29>,
					<1 28 28 28 28 28 28 28 28 28 28>,
					<1 31 31 31 31 31 31 31 31 31 31>;
					rates-ru =
					<4 27 27 27 27 27 27 27 27 27 27 27 27>,
					<1 29 29 29 29 29 29 29 29 29 29 29 29>,
					<1 28 28 28 28 28 28 28 28 28 28 28 28>,
					<1 31 31 31 31 31 31 31 31 31 31 31 31>;
					paths-ofdm = <1 26 26 26 26>;
					paths-ofdm-bf = <1 26 26 26>;
					paths-ru =
					<4 27 27 27 27 27 27 27 27 27 27>,
					<1 29 29 29 29 29 29 29 29 29 29>,
					<1 28 28 28 28 28 28 28 28 28 28>,
					<1 31 31 31 31 31 31 31 31 31 31>;
					paths-ru-bf =
					<3 19 19 19 19 19 19 19 19 19 19>,
					<1 0 19 19 19 19 19 19 19 19 19>,
					<1 0 20 20 20 20 20 20 20 20 20>,
					<1 0 18 18 18 18 18 18 18 18 18>,
					<1 0 20 20 20 20 20 20 20 20 20>;
				};
				r9 {
					channels = <81 81>;
					txs-delta = <0 0 0>;
					rates-ofdm = <25 25 25 25 25 25 25 25>;
					rates-mcs =
					<1 27 27 27 27 27 27 27 27 27 27>,
					<1 29 29 29 29 29 29 29 29 29 29>,
					<1 28 28 28 28 28 28 28 28 28 28>,
					<1 31 31 31 31 31 31 31 31 31 31>;
					rates-ru =
					<4 27 27 27 27 27 27 27 27 27 27 27 27>,
					<1 29 29 29 29 29 29 29 29 29 29 29 29>,
					<1 28 28 28 28 28 28 28 28 28 28 28 28>,
					<1 31 31 31 31 31 31 31 31 31 31 31 31>;
					paths-ofdm = <1 25 25 25 25>;
					paths-ofdm-bf = <1 25 25 25>;
					paths-ru =
					<4 27 27 27 27 27 27 27 27 27 27>,
					<1 29 29 29 29 29 29 29 29 29 29>,
					<1 28 28 28 28 28 28 28 28 28 28>,
					<1 31 31 31 31 31 31 31 31 31 31>;
					paths-ru-bf =
					<3 18 18 18 18 18 18 18 18 18 18>,
					<2 0 18 18 18 18 18 18 18 18 18>,
					<1 0 17 17 17 17 17 17 17 17 17>,
					<1 0 20 20 20 20 20 20 20 20 20>;
				};
				r10 {
					channels = <85 85>;
					txs-delta = <0 0 0>;
					rates-ofdm = <25 25 25 25 25 25 25 25>;
					rates-mcs =
					<1 26 26 26 26 26 26 26 26 26 26>,
					<1 29 29 29 29 29 29 29 29 29 29>,
					<1 28 28 28 28 28 28 28 28 28 28>,
					<1 31 31 31 31 31 31 31 31 31 31>;
					rates-ru =
					<4 26 26 26 26 26 26 26 26 26 26 26 26>,
					<1 29 29 29 29 29 29 29 29 29 29 29 29>,
					<1 28 28 28 28 28 28 28 28 28 28 28 28>,
					<1 31 31 31 31 31 31 31 31 31 31 31 31>;
					paths-ofdm = <1 25 25 25 25>;
					paths-ofdm-bf = <1 25 25 25>;
					paths-ru =
					<4 26 26 26 26 26 26 26 26 26 26>,
					<1 29 29 29 29 29 29 29 29 29 29>,
					<1 28 28 28 28 28 28 28 28 28 28>,
					<1 31 31 31 31 31 31 31 31 31 31>;
					paths-ru-bf =
					<3 18 18 18 18 18 18 18 18 18 18>,
					<2 0 18 18 18 18 18 18 18 18 18>,
					<1 0 17 17 17 17 17 17 17 17 17>,
					<1 0 20 20 20 20 20 20 20 20 20>;
				};
				r11 {
					channels = <89 89>;
					txs-delta = <0 0 0>;
					rates-ofdm = <25 25 25 25 25 25 25 25>;
					rates-mcs =
					<1 26 26 26 26 26 26 26 26 26 26>,
					<2 28 28 28 28 28 28 28 28 28 28>,
					<1 31 31 31 31 31 31 31 31 31 31>;
					rates-ru =
					<4 26 26 26 26 26 26 26 26 26 26 26 26>,
					<2 28 28 28 28 28 28 28 28 28 28 28 28>,
					<1 31 31 31 31 31 31 31 31 31 31 31 31>;
					paths-ofdm = <1 25 25 25 25>;
					paths-ofdm-bf = <1 25 25 25>;
					paths-ru =
					<4 26 26 26 26 26 26 26 26 26 26>,
					<2 28 28 28 28 28 28 28 28 28 28>,
					<1 31 31 31 31 31 31 31 31 31 31>;
					paths-ru-bf =
					<3 17 17 17 17 17 17 17 17 17 17>,
					<3 0 17 17 17 17 17 17 17 17 17>,
					<1 0 20 20 20 20 20 20 20 20 20>;
				};
				r12 {
					channels = <93 233>;
					txs-delta = <0 0 0>;
					rates-ofdm = <24 24 24 24 24 24 24 24>;
					rates-mcs =
					<1 26 26 26 26 26 26 26 26 26 26>,
					<2 28 28 28 28 28 28 28 28 28 28>,
					<1 31 31 31 31 31 31 31 31 31 31>;
					rates-ru =
					<4 26 26 26 26 26 26 26 26 26 26 26 26>,
					<2 28 28 28 28 28 28 28 28 28 28 28 28>,
					<1 31 31 31 31 31 31 31 31 31 31 31 31>;
					paths-ofdm = <1 24 24 24 24>;
					paths-ofdm-bf = <1 24 24 24>;
					paths-ru =
					<4 26 26 26 26 26 26 26 26 26 26>,
					<2 28 28 28 28 28 28 28 28 28 28>,
					<1 31 31 31 31 31 31 31 31 31 31>;
					paths-ru-bf =
					<3 17 17 17 17 17 17 17 17 17 17>,
					<3 0 17 17 17 17 17 17 17 17 17>,
					<1 0 20 20 20 20 20 20 20 20 20>;
				};
			};
		};

		r1 {
			country = "NZ";

			txpower-2g {
				r0 {
					channels = <1 1>;
					txs-delta = <0 0 0>;
					rates-cck = <50 50 50 50>;
					rates-ofdm = <56 56 56 56 56 56 56 56>;
					rates-mcs =
					<4 56 56 56 56 56 56 56 56 56 56>;
					rates-ru =
					<7 56 56 56 56 56 56 56 56 56 56 56 56>;
					paths-cck = <50 50 50 50>;
					paths-ofdm = <1 56 56 56 56>;
					paths-ofdm-bf = <1 50 50 50>;
					paths-ru =
					<5 56 56 56 56 56 56 56 56 56 56>,
					<2 27 27 27 27 27 27 27 27 27 27>;
					paths-ru-bf =
					<3 26 26 26 26 26 26 26 26 26 26>,
					<1 0 26 26 26 26 26 26 26 26 26>,
					<3 0 27 27 27 27 27 27 27 27 27>;
				};
				r1 {
					channels = <2 3>;
					txs-delta = <0 0 0>;
					rates-cck = <51 51 51 51>;
					rates-ofdm = <57 57 57 57 57 57 57 57>;
					rates-mcs =
					<4 56 56 56 56 56 56 56 56 56 56>;
					rates-ru =
					<7 56 56 56 56 56 56 56 56 56 56 56 56>;
					paths-cck = <51 51 51 51>;
					paths-ofdm = <1 57 57 57 57>;
					paths-ofdm-bf = <1 51 51 51>;
					paths-ru =
					<5 56 56 56 56 56 56 56 56 56 56>,
					<2 27 27 27 27 27 27 27 27 27 27>;
					paths-ru-bf =
					<3 26 26 26 26 26 26 26 26 26 26>,
					<1 0 26 26 26 26 26 26 26 26 26>,
					<3 0 27 27 27 27 27 27 27 27 27>;
				};
				r2 {
					channels = <4 5>;
					txs-delta = <0 0 0>;
					rates-cck = <51 51 51 51>;
					rates-ofdm = <57 57 57 57 57 57 57 57>;
					rates-mcs =
					<4 56 56 56 56 56 56 56 56 56 56>;
					rates-ru =
					<7 56 56 56 56 56 56 56 56 56 56 56 56>;
					paths-cck = <51 51 51 51>;
					paths-ofdm = <1 57 57 57 57>;
					paths-ofdm-bf = <1 51 51 51>;
					paths-ru =
					<5 56 56 56 56 56 56 56 56 56 56>,
					<2 26 26 26 26 26 26 26 26 26 26>;
					paths-ru-bf =
					<3 25 25 25 25 25 25 25 25 25 25>,
					<1 0 25 25 25 25 25 25 25 25 25>,
					<3 0 26 26 26 26 26 26 26 26 26>;
				};
				r3 {
					channels = <6 9>;
					txs-delta = <0 0 0>;
					rates-cck = <51 51 51 51>;
					rates-ofdm = <57 57 57 57 57 57 57 57>;
					rates-mcs =
					<4 56 56 56 56 56 56 56 56 56 56>;
					rates-ru =
					<7 56 56 56 56 56 56 56 56 56 56 56 56>;
					paths-cck = <51 51 51 51>;
					paths-ofdm = <1 57 57 57 57>;
					paths-ofdm-bf = <1 51 51 51>;
					paths-ru =
					<5 56 56 56 56 56 56 56 56 56 56>,
					<2 25 25 25 25 25 25 25 25 25 25>;
					paths-ru-bf =
					<3 25 25 25 25 25 25 25 25 25 25>,
					<4 0 25 25 25 25 25 25 25 25 25>;
				};
				r4 {
					channels = <10 10>;
					txs-delta = <0 0 0>;
					rates-cck = <51 51 51 51>;
					rates-ofdm = <57 57 57 57 57 57 57 57>;
					rates-mcs =
					<4 56 56 56 56 56 56 56 56 56 56>;
					rates-ru =
					<7 56 56 56 56 56 56 56 56 56 56 56 56>;
					paths-cck = <51 51 51 51>;
					paths-ofdm = <1 57 57 57 57>;
					paths-ofdm-bf = <1 51 51 51>;
					paths-ru =
					<5 56 56 56 56 56 56 56 56 56 56>,
					<2 26 26 26 26 26 26 26 26 26 26>;
					paths-ru-bf =
					<3 25 25 25 25 25 25 25 25 25 25>,
					<1 0 25 25 25 25 25 25 25 25 25>,
					<3 0 26 26 26 26 26 26 26 26 26>;
				};
				r5 {
					channels = <11 12>;
					txs-delta = <0 0 0>;
					rates-cck = <51 51 51 51>;
					rates-ofdm = <57 57 57 57 57 57 57 57>;
					rates-mcs =
					<1 56 56 56 56 56 56 56 56 56 56>,
					<3 55 55 55 55 55 55 55 55 55 55>;
					rates-ru =
					<4 56 56 56 56 56 56 56 56 56 56 56 56>,
					<3 55 55 55 55 55 55 55 55 55 55 55 55>;
					paths-cck = <51 51 51 51>;
					paths-ofdm = <1 57 57 57 57>;
					paths-ofdm-bf = <1 51 51 51>;
					paths-ru =
					<4 56 56 56 56 56 56 56 56 56 56>,
					<1 55 55 55 55 55 55 55 55 55 55>,
					<2 26 26 26 26 26 26 26 26 26 26>;
					paths-ru-bf =
					<3 25 25 25 25 25 25 25 25 25 25>,
					<1 0 25 25 25 25 25 25 25 25 25>,
					<3 0 26 26 26 26 26 26 26 26 26>;
				};
				r6 {
					channels = <13 13>;
					txs-delta = <0 0 0>;
					rates-cck = <51 51 51 51>;
					rates-ofdm = <56 56 56 56 56 56 56 56>;
					rates-mcs =
					<1 56 56 56 56 56 56 56 56 56 56>,
					<3 55 55 55 55 55 55 55 55 55 55>;
					rates-ru =
					<4 56 56 56 56 56 56 56 56 56 56 56 56>,
					<3 55 55 55 55 55 55 55 55 55 55 55 55>;
					paths-cck = <51 51 51 51>;
					paths-ofdm = <1 56 56 56 56>;
					paths-ofdm-bf = <1 51 51 51>;
					paths-ru =
					<4 56 56 56 56 56 56 56 56 56 56>,
					<1 55 55 55 55 55 55 55 55 55 55>,
					<2 26 26 26 26 26 26 26 26 26 26>;
					paths-ru-bf =
					<3 25 25 25 25 25 25 25 25 25 25>,
					<1 0 25 25 25 25 25 25 25 25 25>,
					<3 0 26 26 26 26 26 26 26 26 26>;
				};
				r7 {
					channels = <14 14>;
					txs-delta = <0 0 0>;
					rates-cck = <50 50 50 50>;
					rates-ofdm = <56 56 56 56 56 56 56 56>;
					rates-mcs =
					<1 56 56 56 56 56 56 56 56 56 56>,
					<1 55 55 55 55 55 55 55 55 55 55>,
					<2 37 37 37 37 37 37 37 37 37 37>;
					rates-ru =
					<4 56 56 56 56 56 56 56 56 56 56 56 56>,
					<3 55 55 55 55 55 55 55 55 55 55 55 55>;
					paths-cck = <50 50 50 50>;
					paths-ofdm = <1 56 56 56 56>;
					paths-ofdm-bf = <1 50 50 50>;
					paths-ru =
					<4 56 56 56 56 56 56 56 56 56 56>,
					<1 55 55 55 55 55 55 55 55 55 55>,
					<2 25 25 25 25 25 25 25 25 25 25>;
					paths-ru-bf =
					<3 25 25 25 25 25 25 25 25 25 25>,
					<4 0 25 25 25 25 25 25 25 25 25>;
				};
			};

			txpower-6g {
				r0 {
					channels = <1 29>;
					txs-delta = <0 0 0>;
					rates-ofdm = <26 26 26 26 26 26 26 26>;
					rates-mcs =
					<1 29 29 29 29 29 29 29 29 29 29>,
					<1 31 31 31 31 31 31 31 31 31 31>,
					<1 29 29 29 29 29 29 29 29 29 29>,
					<1 31 31 31 31 31 31 31 31 31 31>;
					rates-ru =
					<4 29 29 29 29 29 29 29 29 29 29 29 29>,
					<1 31 31 31 31 31 31 31 31 31 31 31 31>,
					<1 29 29 29 29 29 29 29 29 29 29 29 29>,
					<1 31 31 31 31 31 31 31 31 31 31 31 31>;
					paths-ofdm = <1 26 26 26 26>;
					paths-ofdm-bf = <1 26 26 26>;
					paths-ru =
					<4 29 29 29 29 29 29 29 29 29 29>,
					<1 31 31 31 31 31 31 31 31 31 31>,
					<1 29 29 29 29 29 29 29 29 29 29>,
					<1 31 31 31 31 31 31 31 31 31 31>;
					paths-ru-bf =
					<3 20 20 20 20 20 20 20 20 20 20>,
					<1 0 20 20 20 20 20 20 20 20 20>,
					<1 0 21 21 21 21 21 21 21 21 21>,
					<1 0 20 20 20 20 20 20 20 20 20>,
					<1 0 22 22 22 22 22 22 22 22 22>;
				};
				r1 {
					channels = <33 37>;
					txs-delta = <0 0 0>;
					rates-ofdm = <26 26 26 26 26 26 26 26>;
					rates-mcs =
					<1 29 29 29 29 29 29 29 29 29 29>,
					<1 31 31 31 31 31 31 31 31 31 31>,
					<1 29 29 29 29 29 29 29 29 29 29>,
					<1 31 31 31 31 31 31 31 31 31 31>;
					rates-ru =
					<4 29 29 29 29 29 29 29 29 29 29 29 29>,
					<1 31 31 31 31 31 31 31 31 31 31 31 31>,
					<1 29 29 29 29 29 29 29 29 29 29 29 29>,
					<1 31 31 31 31 31 31 31 31 31 31 31 31>;
					paths-ofdm = <1 26 26 26 26>;
					paths-ofdm-bf = <1 26 26 26>;
					paths-ru =
					<4 29 29 29 29 29 29 29 29 29 29>,
					<1 31 31 31 31 31 31 31 31 31 31>,
					<1 29 29 29 29 29 29 29 29 29 29>,
					<1 31 31 31 31 31 31 31 31 31 31>;
					paths-ru-bf =
					<3 20 20 20 20 20 20 20 20 20 20>,
					<1 0 20 20 20 20 20 20 20 20 20>,
					<1 0 21 21 21 21 21 21 21 21 21>,
					<1 0 20 20 20 20 20 20 20 20 20>,
					<1 0 21 21 21 21 21 21 21 21 21>;
				};
				r2 {
					channels = <41 45>;
					txs-delta = <0 0 0>;
					rates-ofdm = <26 26 26 26 26 26 26 26>;
					rates-mcs =
					<1 29 29 29 29 29 29 29 29 29 29>,
					<1 30 30 30 30 30 30 30 30 30 30>,
					<1 29 29 29 29 29 29 29 29 29 29>,
					<1 31 31 31 31 31 31 31 31 31 31>;
					rates-ru =
					<4 29 29 29 29 29 29 29 29 29 29 29 29>,
					<1 30 30 30 30 30 30 30 30 30 30 30 30>,
					<1 29 29 29 29 29 29 29 29 29 29 29 29>,
					<1 31 31 31 31 31 31 31 31 31 31 31 31>;
					paths-ofdm = <1 26 26 26 26>;
					paths-ofdm-bf = <1 26 26 26>;
					paths-ru =
					<4 29 29 29 29 29 29 29 29 29 29>,
					<1 30 30 30 30 30 30 30 30 30 30>,
					<1 29 29 29 29 29 29 29 29 29 29>,
					<1 31 31 31 31 31 31 31 31 31 31>;
					paths-ru-bf =
					<3 20 20 20 20 20 20 20 20 20 20>,
					<1 0 20 20 20 20 20 20 20 20 20>,
					<1 0 21 21 21 21 21 21 21 21 21>,
					<1 0 20 20 20 20 20 20 20 20 20>,
					<1 0 21 21 21 21 21 21 21 21 21>;
				};
				r3 {
					channels = <49 49>;
					txs-delta = <0 0 0>;
					rates-ofdm = <26 26 26 26 26 26 26 26>;
					rates-mcs =
					<1 29 29 29 29 29 29 29 29 29 29>,
					<1 30 30 30 30 30 30 30 30 30 30>,
					<1 29 29 29 29 29 29 29 29 29 29>,
					<1 31 31 31 31 31 31 31 31 31 31>;
					rates-ru =
					<4 29 29 29 29 29 29 29 29 29 29 29 29>,
					<1 30 30 30 30 30 30 30 30 30 30 30 30>,
					<1 29 29 29 29 29 29 29 29 29 29 29 29>,
					<1 31 31 31 31 31 31 31 31 31 31 31 31>;
					paths-ofdm = <1 26 26 26 26>;
					paths-ofdm-bf = <1 26 26 26>;
					paths-ru =
					<4 29 29 29 29 29 29 29 29 29 29>,
					<1 30 30 30 30 30 30 30 30 30 30>,
					<1 29 29 29 29 29 29 29 29 29 29>,
					<1 31 31 31 31 31 31 31 31 31 31>;
					paths-ru-bf =
					<3 20 20 20 20 20 20 20 20 20 20>,
					<1 0 20 20 20 20 20 20 20 20 20>,
					<1 0 21 21 21 21 21 21 21 21 21>,
					<1 0 19 19 19 19 19 19 19 19 19>,
					<1 0 21 21 21 21 21 21 21 21 21>;
				};
				r4 {
					channels = <53 61>;
					txs-delta = <0 0 0>;
					rates-ofdm = <26 26 26 26 26 26 26 26>;
					rates-mcs =
					<1 29 29 29 29 29 29 29 29 29 29>,
					<1 30 30 30 30 30 30 30 30 30 30>,
					<1 28 28 28 28 28 28 28 28 28 28>,
					<1 31 31 31 31 31 31 31 31 31 31>;
					rates-ru =
					<4 29 29 29 29 29 29 29 29 29 29 29 29>,
					<1 30 30 30 30 30 30 30 30 30 30 30 30>,
					<1 28 28 28 28 28 28 28 28 28 28 28 28>,
					<1 31 31 31 31 31 31 31 31 31 31 31 31>;
					paths-ofdm = <1 26 26 26 26>;
					paths-ofdm-bf = <1 26 26 26>;
					paths-ru =
					<4 29 29 29 29 29 29 29 29 29 29>,
					<1 30 30 30 30 30 30 30 30 30 30>,
					<1 28 28 28 28 28 28 28 28 28 28>,
					<1 31 31 31 31 31 31 31 31 31 31>;
					paths-ru-bf =
					<3 20 20 20 20 20 20 20 20 20 20>,
					<1 0 20 20 20 20 20 20 20 20 20>,
					<1 0 21 21 21 21 21 21 21 21 21>,
					<1 0 19 19 19 19 19 19 19 19 19>,
					<1 0 21 21 21 21 21 21 21 21 21>;
				};
				r5 {
					channels = <65 65>;
					txs-delta = <0 0 0>;
					rates-ofdm = <26 26 26 26 26 26 26 26>;
					rates-mcs =
					<1 28 28 28 28 28 28 28 28 28 28>,
					<1 30 30 30 30 30 30 30 30 30 30>,
					<1 28 28 28 28 28 28 28 28 28 28>,
					<1 31 31 31 31 31 31 31 31 31 31>;
					rates-ru =
					<4 28 28 28 28 28 28 28 28 28 28 28 28>,
					<1 30 30 30 30 30 30 30 30 30 30 30 30>,
					<1 28 28 28 28 28 28 28 28 28 28 28 28>,
					<1 31 31 31 31 31 31 31 31 31 31 31 31>;
					paths-ofdm = <1 26 26 26 26>;
					paths-ofdm-bf = <1 26 26 26>;
					paths-ru =
					<4 28 28 28 28 28 28 28 28 28 28>,
					<1 30 30 30 30 30 30 30 30 30 30>,
					<1 28 28 28 28 28 28 28 28 28 28>,
					<1 31 31 31 31 31 31 31 31 31 31>;
					paths-ru-bf =
					<3 20 20 20 20 20 20 20 20 20 20>,
					<1 0 20 20 20 20 20 20 20 20 20>,
					<1 0 21 21 21 21 21 21 21 21 21>,
					<1 0 18 18 18 18 18 18 18 18 18>,
					<1 0 20 20 20 20 20 20 20 20 20>;
				};
				r6 {
					channels = <69 69>;
					txs-delta = <0 0 0>;
					rates-ofdm = <26 26 26 26 26 26 26 26>;
					rates-mcs =
					<1 28 28 28 28 28 28 28 28 28 28>,
					<1 29 29 29 29 29 29 29 29 29 29>,
					<1 28 28 28 28 28 28 28 28 28 28>,
					<1 31 31 31 31 31 31 31 31 31 31>;
					rates-ru =
					<4 28 28 28 28 28 28 28 28 28 28 28 28>,
					<1 29 29 29 29 29 29 29 29 29 29 29 29>,
					<1 28 28 28 28 28 28 28 28 28 28 28 28>,
					<1 31 31 31 31 31 31 31 31 31 31 31 31>;
					paths-ofdm = <1 26 26 26 26>;
					paths-ofdm-bf = <1 26 26 26>;
					paths-ru =
					<4 28 28 28 28 28 28 28 28 28 28>,
					<1 29 29 29 29 29 29 29 29 29 29>,
					<1 28 28 28 28 28 28 28 28 28 28>,
					<1 31 31 31 31 31 31 31 31 31 31>;
					paths-ru-bf =
					<3 20 20 20 20 20 20 20 20 20 20>,
					<1 0 20 20 20 20 20 20 20 20 20>,
					<1 0 21 21 21 21 21 21 21 21 21>,
					<1 0 18 18 18 18 18 18 18 18 18>,
					<1 0 20 20 20 20 20 20 20 20 20>;
				};
				r7 {
					channels = <73 73>;
					txs-delta = <0 0 0>;
					rates-ofdm = <26 26 26 26 26 26 26 26>;
					rates-mcs =
					<1 28 28 28 28 28 28 28 28 28 28>,
					<1 29 29 29 29 29 29 29 29 29 29>,
					<1 28 28 28 28 28 28 28 28 28 28>,
					<1 31 31 31 31 31 31 31 31 31 31>;
					rates-ru =
					<4 28 28 28 28 28 28 28 28 28 28 28 28>,
					<1 29 29 29 29 29 29 29 29 29 29 29 29>,
					<1 28 28 28 28 28 28 28 28 28 28 28 28>,
					<1 31 31 31 31 31 31 31 31 31 31 31 31>;
					paths-ofdm = <1 26 26 26 26>;
					paths-ofdm-bf = <1 26 26 26>;
					paths-ru =
					<4 28 28 28 28 28 28 28 28 28 28>,
					<1 29 29 29 29 29 29 29 29 29 29>,
					<1 28 28 28 28 28 28 28 28 28 28>,
					<1 31 31 31 31 31 31 31 31 31 31>;
					paths-ru-bf =
					<3 19 19 19 19 19 19 19 19 19 19>,
					<1 0 19 19 19 19 19 19 19 19 19>,
					<1 0 20 20 20 20 20 20 20 20 20>,
					<1 0 18 18 18 18 18 18 18 18 18>,
					<1 0 20 20 20 20 20 20 20 20 20>;
				};
				r8 {
					channels = <77 77>;
					txs-delta = <0 0 0>;
					rates-ofdm = <26 26 26 26 26 26 26 26>;
					rates-mcs =
					<1 27 27 27 27 27 27 27 27 27 27>,
					<1 29 29 29 29 29 29 29 29 29 29>,
					<1 28 28 28 28 28 28 28 28 28 28>,
					<1 31 31 31 31 31 31 31 31 31 31>;
					rates-ru =
					<4 27 27 27 27 27 27 27 27 27 27 27 27>,
					<1 29 29 29 29 29 29 29 29 29 29 29 29>,
					<1 28 28 28 28 28 28 28 28 28 28 28 28>,
					<1 31 31 31 31 31 31 31 31 31 31 31 31>;
					paths-ofdm = <1 26 26 26 26>;
					paths-ofdm-bf = <1 26 26 26>;
					paths-ru =
					<4 27 27 27 27 27 27 27 27 27 27>,
					<1 29 29 29 29 29 29 29 29 29 29>,
					<1 28 28 28 28 28 28 28 28 28 28>,
					<1 31 31 31 31 31 31 31 31 31 31>;
					paths-ru-bf =
					<3 19 19 19 19 19 19 19 19 19 19>,
					<1 0 19 19 19 19 19 19 19 19 19>,
					<1 0 20 20 20 20 20 20 20 20 20>,
					<1 0 18 18 18 18 18 18 18 18 18>,
					<1 0 20 20 20 20 20 20 20 20 20>;
				};
				r9 {
					channels = <81 81>;
					txs-delta = <0 0 0>;
					rates-ofdm = <25 25 25 25 25 25 25 25>;
					rates-mcs =
					<1 27 27 27 27 27 27 27 27 27 27>,
					<1 29 29 29 29 29 29 29 29 29 29>,
					<1 28 28 28 28 28 28 28 28 28 28>,
					<1 31 31 31 31 31 31 31 31 31 31>;
					rates-ru =
					<4 27 27 27 27 27 27 27 27 27 27 27 27>,
					<1 29 29 29 29 29 29 29 29 29 29 29 29>,
					<1 28 28 28 28 28 28 28 28 28 28 28 28>,
					<1 31 31 31 31 31 31 31 31 31 31 31 31>;
					paths-ofdm = <1 25 25 25 25>;
					paths-ofdm-bf = <1 25 25 25>;
					paths-ru =
					<4 27 27 27 27 27 27 27 27 27 27>,
					<1 29 29 29 29 29 29 29 29 29 29>,
					<1 28 28 28 28 28 28 28 28 28 28>,
					<1 31 31 31 31 31 31 31 31 31 31>;
					paths-ru-bf =
					<3 18 18 18 18 18 18 18 18 18 18>,
					<2 0 18 18 18 18 18 18 18 18 18>,
					<1 0 17 17 17 17 17 17 17 17 17>,
					<1 0 20 20 20 20 20 20 20 20 20>;
				};
				r10 {
					channels = <85 85>;
					txs-delta = <0 0 0>;
					rates-ofdm = <25 25 25 25 25 25 25 25>;
					rates-mcs =
					<1 26 26 26 26 26 26 26 26 26 26>,
					<1 29 29 29 29 29 29 29 29 29 29>,
					<1 28 28 28 28 28 28 28 28 28 28>,
					<1 31 31 31 31 31 31 31 31 31 31>;
					rates-ru =
					<4 26 26 26 26 26 26 26 26 26 26 26 26>,
					<1 29 29 29 29 29 29 29 29 29 29 29 29>,
					<1 28 28 28 28 28 28 28 28 28 28 28 28>,
					<1 31 31 31 31 31 31 31 31 31 31 31 31>;
					paths-ofdm = <1 25 25 25 25>;
					paths-ofdm-bf = <1 25 25 25>;
					paths-ru =
					<4 26 26 26 26 26 26 26 26 26 26>,
					<1 29 29 29 29 29 29 29 29 29 29>,
					<1 28 28 28 28 28 28 28 28 28 28>,
					<1 31 31 31 31 31 31 31 31 31 31>;
					paths-ru-bf =
					<3 18 18 18 18 18 18 18 18 18 18>,
					<2 0 18 18 18 18 18 18 18 18 18>,
					<1 0 17 17 17 17 17 17 17 17 17>,
					<1 0 20 20 20 20 20 20 20 20 20>;
				};
				r11 {
					channels = <89 89>;
					txs-delta = <0 0 0>;
					rates-ofdm = <25 25 25 25 25 25 25 25>;
					rates-mcs =
					<1 26 26 26 26 26 26 26 26 26 26>,
					<2 28 28 28 28 28 28 28 28 28 28>,
					<1 31 31 31 31 31 31 31 31 31 31>;
					rates-ru =
					<4 26 26 26 26 26 26 26 26 26 26 26 26>,
					<2 28 28 28 28 28 28 28 28 28 28 28 28>,
					<1 31 31 31 31 31 31 31 31 31 31 31 31>;
					paths-ofdm = <1 25 25 25 25>;
					paths-ofdm-bf = <1 25 25 25>;
					paths-ru =
					<4 26 26 26 26 26 26 26 26 26 26>,
					<2 28 28 28 28 28 28 28 28 28 28>,
					<1 31 31 31 31 31 31 31 31 31 31>;
					paths-ru-bf =
					<3 17 17 17 17 17 17 17 17 17 17>,
					<3 0 17 17 17 17 17 17 17 17 17>,
					<1 0 20 20 20 20 20 20 20 20 20>;
				};
				r12 {
					channels = <93 233>;
					txs-delta = <0 0 0>;
					rates-ofdm = <24 24 24 24 24 24 24 24>;
					rates-mcs =
					<1 26 26 26 26 26 26 26 26 26 26>,
					<2 28 28 28 28 28 28 28 28 28 28>,
					<1 31 31 31 31 31 31 31 31 31 31>;
					rates-ru =
					<4 26 26 26 26 26 26 26 26 26 26 26 26>,
					<2 28 28 28 28 28 28 28 28 28 28 28 28>,
					<1 31 31 31 31 31 31 31 31 31 31 31 31>;
					paths-ofdm = <1 24 24 24 24>;
					paths-ofdm-bf = <1 24 24 24>;
					paths-ru =
					<4 26 26 26 26 26 26 26 26 26 26>,
					<2 28 28 28 28 28 28 28 28 28 28>,
					<1 31 31 31 31 31 31 31 31 31 31>;
					paths-ru-bf =
					<3 17 17 17 17 17 17 17 17 17 17>,
					<3 0 17 17 17 17 17 17 17 17 17>,
					<1 0 20 20 20 20 20 20 20 20 20>;
				};
			};
		};
	};
};
